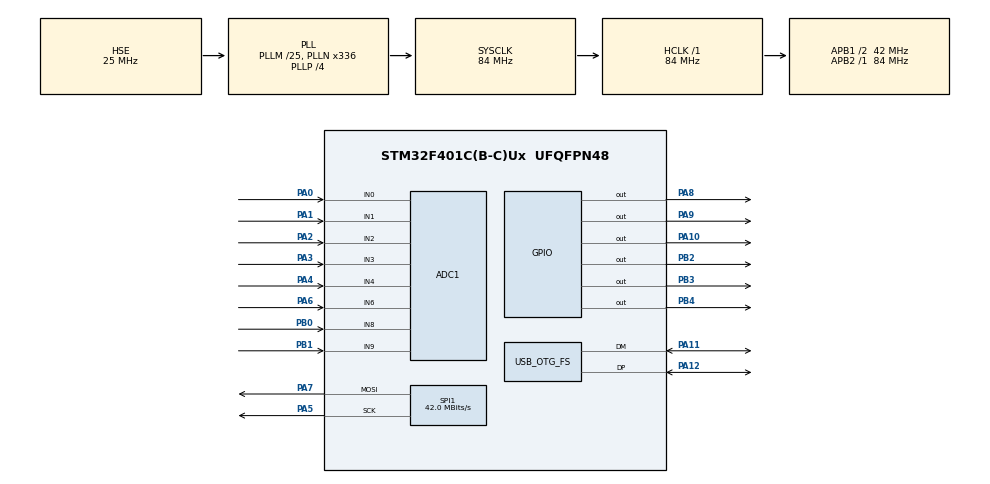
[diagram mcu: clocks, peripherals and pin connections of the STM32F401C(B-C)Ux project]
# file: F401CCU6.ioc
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ADC1.Channel-0\#ChannelRegularConversion=ADC_CHANNEL_0
ADC1.Channel-1\#ChannelRegularConversion=ADC_CHANNEL_1
ADC1.ContinuousConvMode=ENABLE
ADC1.DMAContinuousRequests=ENABLE
ADC1.EOCSelection=ADC_EOC_SEQ_CONV
ADC1.EnableAnalogWatchDog=true
ADC1.HighThreshold=1241
ADC1.ITMode=ENABLE
ADC1.InjNumberOfConversion=0
ADC1.NbrOfConversion=2
ADC1.NbrOfConversionFlag=1
ADC1.Rank-0\#ChannelRegularConversion=1
ADC1.Rank-1\#ChannelRegularConversion=2
ADC1.SamplingTime-0\#ChannelRegularConversion=ADC_SAMPLETIME_480CYCLES
ADC1.SamplingTime-1\#ChannelRegularConversion=ADC_SAMPLETIME_480CYCLES
ADC1.WatchdogMode=ADC_ANALOGWATCHDOG_SINGLE_REG
ADC1.master=1
Dma.ADC1.0.Direction=DMA_PERIPH_TO_MEMORY
Dma.ADC1.0.FIFOMode=DMA_FIFOMODE_DISABLE
Dma.ADC1.0.Instance=DMA2_Stream0
Dma.ADC1.0.MemDataAlignment=DMA_MDATAALIGN_HALFWORD
Dma.ADC1.0.MemInc=DMA_MINC_ENABLE
Dma.ADC1.0.Mode=DMA_CIRCULAR
Dma.ADC1.0.PeriphDataAlignment=DMA_PDATAALIGN_HALFWORD
Dma.ADC1.0.PeriphInc=DMA_PINC_DISABLE
Dma.ADC1.0.Priority=DMA_PRIORITY_LOW
Dma.Request0=ADC1
Mcu.Family=STM32F4
Mcu.Name=STM32F401C(B-C)Ux
Mcu.Package=UFQFPN48
NVIC.ADC_IRQn=true\:0\:0\:false\:false\:true\:true\:true
NVIC.DMA2_Stream0_IRQn=true\:0\:0\:false\:false\:true\:false\:true
NVIC.OTG_FS_IRQn=true\:0\:0\:false\:false\:true\:false\:true
NVIC.PriorityGroup=NVIC_PRIORITYGROUP_4
NVIC.TIM1_TRG_COM_TIM11_IRQn=true\:0\:0\:false\:false\:true\:true\:true
PA0-WKUP.Signal=ADCx_IN0
PA1.Signal=ADCx_IN1
PA10.Signal=GPIO_Output
PA11.Mode=Device_Only
PA11.Signal=USB_OTG_FS_DM
PA12.Mode=Device_Only
PA12.Signal=USB_OTG_FS_DP
PA13.Mode=Serial_Wire
PA13.Signal=SYS_JTMS-SWDIO
PA14.Mode=Serial_Wire
PA14.Signal=SYS_JTCK-SWCLK
PA2.Signal=ADCx_IN2
PA3.Signal=ADCx_IN3
PA4.Signal=ADCx_IN4
PA5.Mode=TX_Only_Simplex_Unidirect_Master
PA5.Signal=SPI1_SCK
PA6.Signal=ADCx_IN6
PA7.Mode=TX_Only_Simplex_Unidirect_Master
PA7.Signal=SPI1_MOSI
PA8.Signal=GPIO_Output
PA9.Signal=GPIO_Output
PB0.Signal=ADCx_IN8
PB1.Signal=ADCx_IN9
PB2.Signal=GPIO_Output
PB3.Signal=GPIO_Output
PB4.Signal=GPIO_Output
PH0\ -\ OSC_IN.Mode=HSE-External-Oscillator
PH0\ -\ OSC_IN.Signal=RCC_OSC_IN
PH1\ -\ OSC_OUT.Mode=HSE-External-Oscillator
PH1\ -\ OSC_OUT.Signal=RCC_OSC_OUT
ProjectManager.HeapSize=0x200
ProjectManager.StackSize=0x400
ProjectManager.TargetToolchain=MDK-ARM V5.32
RCC.48MHZClocksFreq_Value=48000000
RCC.AHBFreq_Value=84000000
RCC.APB1CLKDivider=RCC_HCLK_DIV2
RCC.APB1Freq_Value=42000000
RCC.APB1TimFreq_Value=84000000
RCC.APB2Freq_Value=84000000
RCC.APB2TimFreq_Value=84000000
RCC.CortexFreq_Value=84000000
RCC.HCLKFreq_Value=84000000
RCC.HSE_VALUE=25000000
RCC.HSI_VALUE=16000000
RCC.LSE_VALUE=32768
RCC.PLLM=25
RCC.PLLN=336
RCC.PLLP=RCC_PLLP_DIV4
RCC.PLLQ=7
RCC.SYSCLKFreq_VALUE=84000000
RCC.SYSCLKSource=RCC_SYSCLKSOURCE_PLLCLK
RCC.VCOOutputFreq_Value=336000000
SH.ADCx_IN0.0=ADC1_IN0,IN0
SH.ADCx_IN1.0=ADC1_IN1,IN1
SH.ADCx_IN2.0=ADC1_IN2,IN2
SH.ADCx_IN3.0=ADC1_IN3,IN3
SH.ADCx_IN4.0=ADC1_IN4,IN4
SH.ADCx_IN6.0=ADC1_IN6,IN6
SH.ADCx_IN8.0=ADC1_IN8,IN8
SH.ADCx_IN9.0=ADC1_IN9,IN9
SPI1.CalculateBaudRate=42.0 MBits/s
SPI1.Direction=SPI_DIRECTION_2LINES
SPI1.Mode=SPI_MODE_MASTER
SPI1.VirtualType=VM_MASTER
TIM11.AutoReloadPreload=TIM_AUTORELOAD_PRELOAD_ENABLE
TIM11.Period=1000-1
TIM11.Prescaler=83
USB_DEVICE.CLASS_NAME_FS=CDC
USB_DEVICE.VirtualMode=Cdc
USB_DEVICE.VirtualModeFS=Cdc_FS
USB_OTG_FS.VirtualMode=Device_Only
VP_TIM11_VS_ClockSourceINT.Mode=Enable_Timer
VP_USB_DEVICE_VS_USB_DEVICE_CDC_FS.Mode=CDC_FS
board=custom

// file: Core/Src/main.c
/* USER CODE BEGIN Header */
/**
  ******************************************************************************
  * @file           : main.c
  * @brief          : Main program body
  ******************************************************************************
  * @attention
  *
  * <h2><center>&copy; Copyright (c) 2021 STMicroelectronics.
  * All rights reserved.</center></h2>
  *
  * This software component is licensed by ST under Ultimate Liberty license
  * SLA0044, the "License"; You may not use this file except in compliance with
  * the License. You may obtain a copy of the License at:
  *                             www.st.com/SLA0044
  *
  ******************************************************************************
  */
/* USER CODE END Header */
#include "main.h"
#include "adc.h"
#include "dma.h"
#include "spi.h"
#include "tim.h"
#include "usb_device.h"
#include "gpio.h"

/* USER CODE BEGIN Includes */
#include "usbd_cdc_if.h"
#include "stdint.h"
#include "fun.h"
#include "test.h"
/* USER CODE END Includes */

/* USER CODE BEGIN PV */
uint16_t ADC_CONV;
uint32_t tickstart;
extern uint8_t fpsMs;
/* USER CODE END PV */

void SystemClock_Config(void);

int main(void)
{

  /* MCU Configuration--------------------------------------------------------*/

  /* Reset of all peripherals, Initializes the Flash interface and the Systick. */
  HAL_Init();

  /* Configure the system clock */
  SystemClock_Config();

  /* Initialize all configured peripherals */
  MX_GPIO_Init();
  MX_DMA_Init();
  MX_USB_DEVICE_Init();
  MX_ADC1_Init();
  MX_TIM11_Init();
  MX_SPI1_Init();
  /* USER CODE BEGIN 2 */
	HAL_ADC_Start_DMA(&hadc1,(uint32_t *)&ADC_CONV,1);
	HAL_TIM_Base_Start_IT(&htim11);
	LCD_Init();               //初始化OLED接口
	fpsMs=1000/30;
	HAL_GPIO_WritePin(GPIOB,GPIO_PIN_2,GPIO_PIN_SET);

	tickstart=HAL_GetTick();
  /* USER CODE END 2 */

  /* Infinite loop */
  while (1)
  {

    /* USER CODE BEGIN 3 */
		Update();
		//OledPrintf("%d\n",tickstart);
		//usb_printf("%d\n",HAL_GetTick());

  }
  /* USER CODE END 3 */
}

void SystemClock_Config(void)
{
  RCC_OscInitTypeDef RCC_OscInitStruct = {0};
  RCC_ClkInitTypeDef RCC_ClkInitStruct = {0};

  /** Configure the main internal regulator output voltage
  */
  __HAL_RCC_PWR_CLK_ENABLE();
  __HAL_PWR_VOLTAGESCALING_CONFIG(PWR_REGULATOR_VOLTAGE_SCALE2);
  /** Initializes the RCC Oscillators according to the specified parameters
  * in the RCC_OscInitTypeDef structure.
  */
  RCC_OscInitStruct.OscillatorType = RCC_OSCILLATORTYPE_HSE;
  RCC_OscInitStruct.HSEState = RCC_HSE_ON;
  RCC_OscInitStruct.PLL.PLLState = RCC_PLL_ON;
  RCC_OscInitStruct.PLL.PLLSource = RCC_PLLSOURCE_HSE;
  RCC_OscInitStruct.PLL.PLLM = 25;
  RCC_OscInitStruct.PLL.PLLN = 336;
  RCC_OscInitStruct.PLL.PLLP = RCC_PLLP_DIV4;
  RCC_OscInitStruct.PLL.PLLQ = 7;
  if (HAL_RCC_OscConfig(&RCC_OscInitStruct) != HAL_OK)
  {
    Error_Handler();
  }
  /** Initializes the CPU, AHB and APB buses clocks
  */
  RCC_ClkInitStruct.ClockType = RCC_CLOCKTYPE_HCLK|RCC_CLOCKTYPE_SYSCLK
                              |RCC_CLOCKTYPE_PCLK1|RCC_CLOCKTYPE_PCLK2;
  RCC_ClkInitStruct.SYSCLKSource = RCC_SYSCLKSOURCE_PLLCLK;
  RCC_ClkInitStruct.AHBCLKDivider = RCC_SYSCLK_DIV1;
  RCC_ClkInitStruct.APB1CLKDivider = RCC_HCLK_DIV2;
  RCC_ClkInitStruct.APB2CLKDivider = RCC_HCLK_DIV1;

  if (HAL_RCC_ClockConfig(&RCC_ClkInitStruct, FLASH_LATENCY_2) != HAL_OK)
  {
    Error_Handler();
  }
}

void Error_Handler(void)
{
  __disable_irq();
  while (1)
  {
  }
}

/************************ (C) COPYRIGHT STMicroelectronics *****END OF FILE****/
